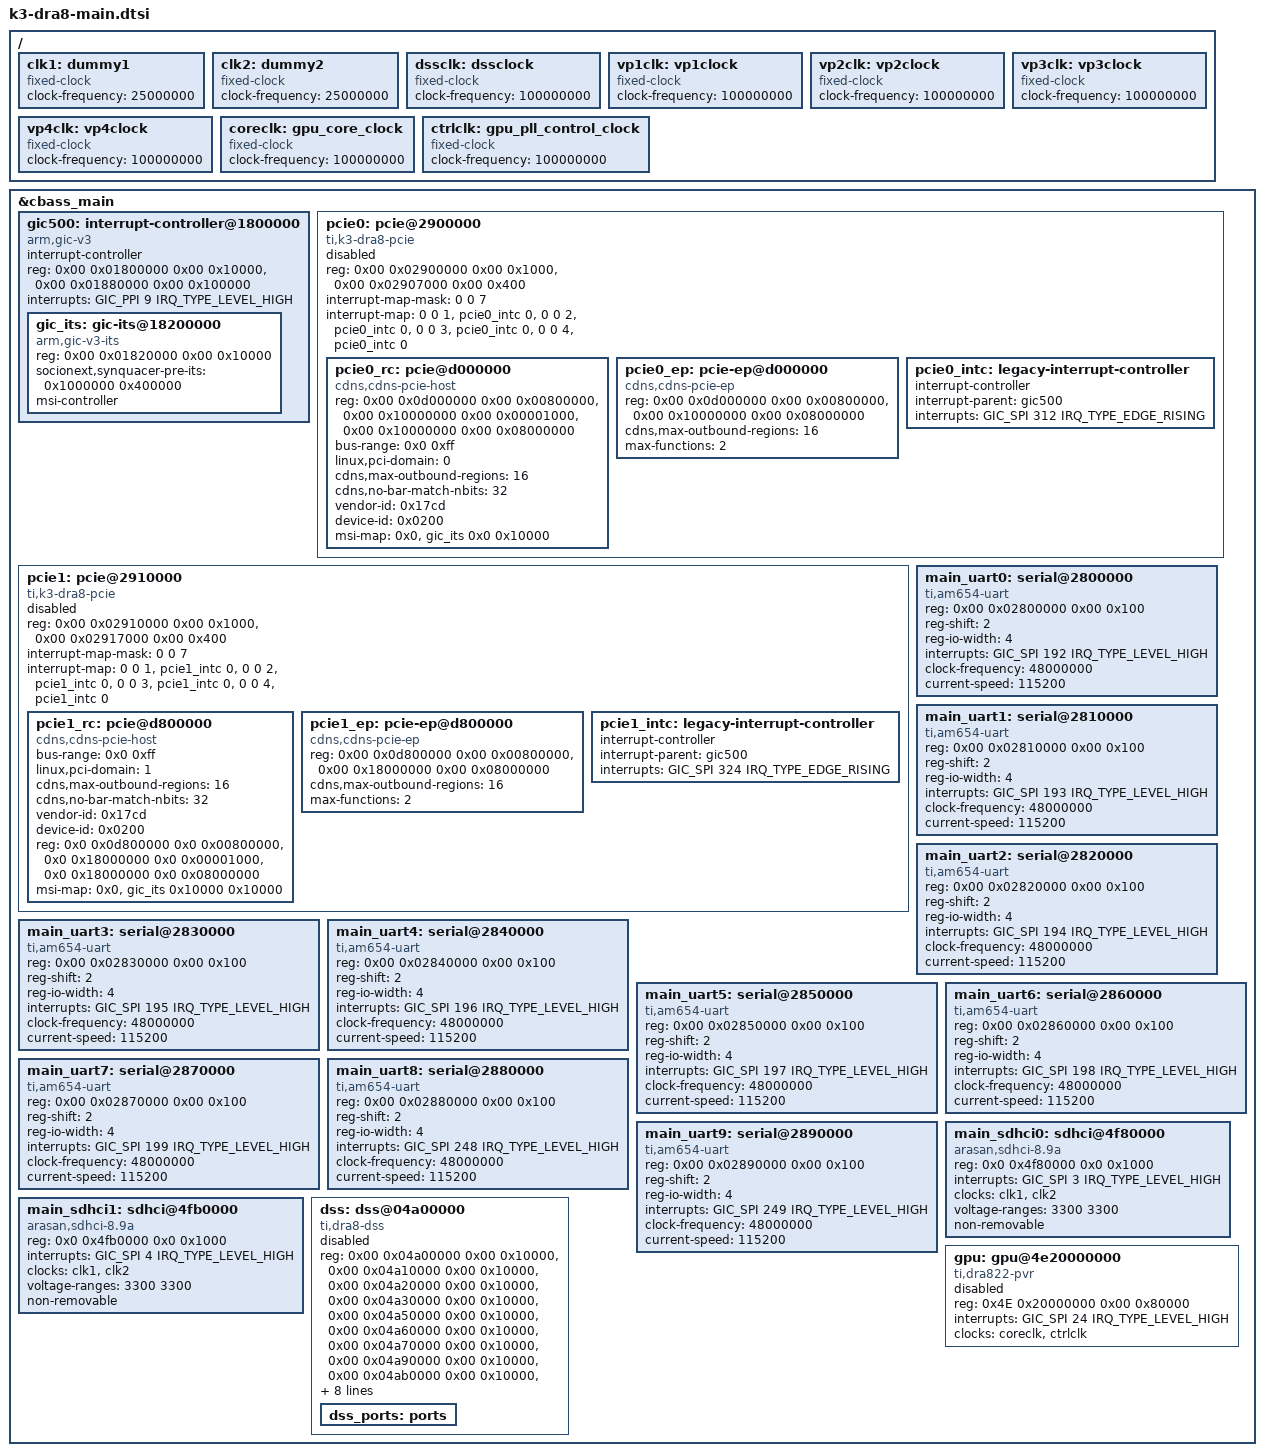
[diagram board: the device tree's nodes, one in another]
// SPDX-License-Identifier: GPL-2.0
/*
 * Device Tree Source for DRA8 SoC Family Main Domain peripherals
 *
 * Copyright (C) 2016-2018 Texas Instruments Incorporated - http://www.ti.com/
 */

/ {
	clk1: dummy1 {
		compatible = "fixed-clock";
		#clock-cells = <0>;
		clock-frequency = <25000000>;
	};

	clk2: dummy2 {
		compatible = "fixed-clock";
		#clock-cells = <0>;
		clock-frequency = <25000000>;
	};

	dssclk: dssclock {
		compatible = "fixed-clock";
		#clock-cells = <0>;
		clock-frequency = <100000000>;
	};

	vp1clk: vp1clock {
		compatible = "fixed-clock";
		#clock-cells = <0>;
		clock-frequency = <100000000>;
	};

	vp2clk: vp2clock {
		compatible = "fixed-clock";
		#clock-cells = <0>;
		clock-frequency = <100000000>;
	};

	vp3clk: vp3clock {
		compatible = "fixed-clock";
		#clock-cells = <0>;
		clock-frequency = <100000000>;
	};

	vp4clk: vp4clock {
		compatible = "fixed-clock";
		#clock-cells = <0>;
		clock-frequency = <100000000>;
	};

	coreclk: gpu_core_clock {
		compatible = "fixed-clock";
		#clock-cells = <0>;
		clock-frequency = <100000000>;
	};

	ctrlclk: gpu_pll_control_clock {
		compatible = "fixed-clock";
		#clock-cells = <0>;
		clock-frequency = <100000000>;
	};
};

&cbass_main {
	gic500: interrupt-controller@1800000 {
		compatible = "arm,gic-v3";
		#address-cells = <2>;
		#size-cells = <2>;
		ranges;
		#interrupt-cells = <3>;
		interrupt-controller;
		reg = <0x00 0x01800000 0x00 0x10000>,	/* GICD */
		      <0x00 0x01880000 0x00 0x100000>;	/* GICR */
		/*
		 * vcpumntirq:
		 * virtual CPU interface maintenance interrupt
		 */
		interrupts = <GIC_PPI 9 IRQ_TYPE_LEVEL_HIGH>;

		gic_its: gic-its@18200000 {
			compatible = "arm,gic-v3-its";
			reg = <0x00 0x01820000 0x00 0x10000>;
			socionext,synquacer-pre-its = <0x1000000 0x400000>;
			msi-controller;
			#msi-cells = <1>;
		};
	};

	pcie0: pcie@2900000 {
		compatible = "ti,k3-dra8-pcie";
		reg = <0x00 0x02900000 0x00 0x1000>,
		      <0x00 0x02907000 0x00 0x400>;
		reg-names = "intd_cfg", "user_cfg";
		#address-cells = <2>;
		#size-cells = <2>;
		ranges;
		#interrupt-cells = <1>;
		interrupt-map-mask = <0 0 7>;
		interrupt-map = <0 0 1 &pcie0_intc 0>, /* INT A */
				<0 0 2 &pcie0_intc 0>, /* INT B */
				<0 0 3 &pcie0_intc 0>, /* INT C */
				<0 0 4 &pcie0_intc 0>; /* INT D */
		status = "disabled";

		pcie0_rc: pcie@d000000 {
			compatible = "cdns,cdns-pcie-host";
			reg = <0x00 0x0d000000 0x00 0x00800000>,
			      <0x00 0x10000000 0x00 0x00001000>,
			      <0x00 0x10000000 0x00 0x08000000>;
			reg-names = "reg", "cfg", "mem";
			device_type = "pci";
			#address-cells = <3>;
			#size-cells = <2>;
			bus-range = <0x0 0xff>;
			linux,pci-domain = <0>;
			cdns,max-outbound-regions = <16>;
			cdns,no-bar-match-nbits = <32>;
			vendor-id = /bits/ 16 <0x17cd>;
			device-id = /bits/ 16 <0x0200>;
			msi-map = <0x0 &gic_its 0x0 0x10000>;
			ranges = <0x01000000 0x0 0x10001000  0x00 0x10001000  0x0 0x0010000>,
				 <0x02000000 0x0 0x10011000  0x00 0x10011000  0x0 0x7fef000>;
		};

		pcie0_ep: pcie-ep@d000000 {
			compatible = "cdns,cdns-pcie-ep";
			reg = <0x00 0x0d000000 0x00 0x00800000>,
			      <0x00 0x10000000 0x00 0x08000000>;
			reg-names = "reg", "mem";
			cdns,max-outbound-regions = <16>;
			max-functions = /bits/ 8 <2>;
		};

		pcie0_intc: legacy-interrupt-controller {
			interrupt-controller;
			#interrupt-cells = <1>;
			interrupt-parent = <&gic500>;
			interrupts = <GIC_SPI 312 IRQ_TYPE_EDGE_RISING>;
		};
	};

	pcie1: pcie@2910000 {
		compatible = "ti,k3-dra8-pcie";
		reg = <0x00 0x02910000 0x00 0x1000>,
		      <0x00 0x02917000 0x00 0x400>;
		reg-names = "intd_cfg", "user_cfg";
		#address-cells = <2>;
		#size-cells = <2>;
		ranges;
		#interrupt-cells = <1>;
		interrupt-map-mask = <0 0 7>;
		interrupt-map = <0 0 1 &pcie1_intc 0>, /* INT A */
				<0 0 2 &pcie1_intc 0>, /* INT B */
				<0 0 3 &pcie1_intc 0>, /* INT C */
				<0 0 4 &pcie1_intc 0>; /* INT D */
		status = "disabled";

		pcie1_rc: pcie@d800000 {
			compatible = "cdns,cdns-pcie-host";
			device_type = "pci";
			#address-cells = <3>;
			#size-cells = <2>;
			bus-range = <0x0 0xff>;
			linux,pci-domain = <1>;
			cdns,max-outbound-regions = <16>;
			cdns,no-bar-match-nbits = <32>;
			vendor-id = /bits/ 16 <0x17cd>;
			device-id = /bits/ 16 <0x0200>;
			reg = <0x0 0x0d800000 0x0 0x00800000>,
			      <0x0 0x18000000 0x0 0x00001000>,
			      <0x0 0x18000000 0x0 0x08000000>;
			reg-names = "reg", "cfg", "mem";
			msi-map = <0x0 &gic_its 0x10000 0x10000>;
			ranges = <0x01000000 0x0 0x18001000  0x00 0x18001000  0x0 0x0010000>,
				 <0x02000000 0x0 0x18011000  0x00 0x18011000  0x0 0x7fef000>;
		};

		pcie1_ep: pcie-ep@d800000 {
			compatible = "cdns,cdns-pcie-ep";
			reg = <0x00 0x0d800000 0x00 0x00800000>,
			      <0x00 0x18000000 0x00 0x08000000>;
			reg-names = "reg", "mem";
			cdns,max-outbound-regions = <16>;
			max-functions = /bits/ 8 <2>;
		};

		pcie1_intc: legacy-interrupt-controller {
			interrupt-controller;
			#interrupt-cells = <1>;
			interrupt-parent = <&gic500>;
			interrupts = <GIC_SPI 324 IRQ_TYPE_EDGE_RISING>;
		};
	};

	main_uart0: serial@2800000 {
		compatible = "ti,am654-uart";
		reg = <0x00 0x02800000 0x00 0x100>;
		reg-shift = <2>;
		reg-io-width = <4>;
		interrupts = <GIC_SPI 192 IRQ_TYPE_LEVEL_HIGH>;
		clock-frequency = <48000000>;
		current-speed = <115200>;
	};

	main_uart1: serial@2810000 {
		compatible = "ti,am654-uart";
		reg = <0x00 0x02810000 0x00 0x100>;
		reg-shift = <2>;
		reg-io-width = <4>;
		interrupts = <GIC_SPI 193 IRQ_TYPE_LEVEL_HIGH>;
		clock-frequency = <48000000>;
		current-speed = <115200>;
	};

	main_uart2: serial@2820000 {
		compatible = "ti,am654-uart";
		reg = <0x00 0x02820000 0x00 0x100>;
		reg-shift = <2>;
		reg-io-width = <4>;
		interrupts = <GIC_SPI 194 IRQ_TYPE_LEVEL_HIGH>;
		clock-frequency = <48000000>;
		current-speed = <115200>;
	};

	main_uart3: serial@2830000 {
		compatible = "ti,am654-uart";
		reg = <0x00 0x02830000 0x00 0x100>;
		reg-shift = <2>;
		reg-io-width = <4>;
		interrupts = <GIC_SPI 195 IRQ_TYPE_LEVEL_HIGH>;
		clock-frequency = <48000000>;
		current-speed = <115200>;
	};

	main_uart4: serial@2840000 {
		compatible = "ti,am654-uart";
		reg = <0x00 0x02840000 0x00 0x100>;
		reg-shift = <2>;
		reg-io-width = <4>;
		interrupts = <GIC_SPI 196 IRQ_TYPE_LEVEL_HIGH>;
		clock-frequency = <48000000>;
		current-speed = <115200>;
	};

	main_uart5: serial@2850000 {
		compatible = "ti,am654-uart";
		reg = <0x00 0x02850000 0x00 0x100>;
		reg-shift = <2>;
		reg-io-width = <4>;
		interrupts = <GIC_SPI 197 IRQ_TYPE_LEVEL_HIGH>;
		clock-frequency = <48000000>;
		current-speed = <115200>;
	};

	main_uart6: serial@2860000 {
		compatible = "ti,am654-uart";
		reg = <0x00 0x02860000 0x00 0x100>;
		reg-shift = <2>;
		reg-io-width = <4>;
		interrupts = <GIC_SPI 198 IRQ_TYPE_LEVEL_HIGH>;
		clock-frequency = <48000000>;
		current-speed = <115200>;
	};

	main_uart7: serial@2870000 {
		compatible = "ti,am654-uart";
		reg = <0x00 0x02870000 0x00 0x100>;
		reg-shift = <2>;
		reg-io-width = <4>;
		interrupts = <GIC_SPI 199 IRQ_TYPE_LEVEL_HIGH>;
		clock-frequency = <48000000>;
		current-speed = <115200>;
	};

	main_uart8: serial@2880000 {
		compatible = "ti,am654-uart";
		reg = <0x00 0x02880000 0x00 0x100>;
		reg-shift = <2>;
		reg-io-width = <4>;
		interrupts = <GIC_SPI 248 IRQ_TYPE_LEVEL_HIGH>;
		clock-frequency = <48000000>;
		current-speed = <115200>;
	};

	main_uart9: serial@2890000 {
		compatible = "ti,am654-uart";
		reg = <0x00 0x02890000 0x00 0x100>;
		reg-shift = <2>;
		reg-io-width = <4>;
		interrupts = <GIC_SPI 249 IRQ_TYPE_LEVEL_HIGH>;
		clock-frequency = <48000000>;
		current-speed = <115200>;
	};

	main_sdhci0: sdhci@4f80000 {
		compatible = "arasan,sdhci-8.9a";
		reg = <0x0 0x4f80000 0x0 0x1000>;
		interrupts = <GIC_SPI 3 IRQ_TYPE_LEVEL_HIGH>;
		clock-names = "clk_xin", "clk_ahb";
		clocks = <&clk1>, <&clk2>;
		voltage-ranges = <3300 3300>;
		non-removable;
	};

	main_sdhci1: sdhci@4fb0000 {
		compatible = "arasan,sdhci-8.9a";
		reg = <0x0 0x4fb0000 0x0 0x1000>;
		interrupts = <GIC_SPI 4 IRQ_TYPE_LEVEL_HIGH>;
		clock-names = "clk_xin", "clk_ahb";
		clocks = <&clk1>, <&clk2>;
		voltage-ranges = <3300 3300>;
		non-removable;
	};

	dss: dss@04a00000 {
		compatible = "ti,dra8-dss";
		reg =
			<0x00 0x04a00000 0x00 0x10000>, /* common */
			<0x00 0x04a10000 0x00 0x10000>, /* common1*/

			<0x00 0x04a20000 0x00 0x10000>, /* vidl1 */
			<0x00 0x04a30000 0x00 0x10000>, /* vidl2 */
			<0x00 0x04a50000 0x00 0x10000>, /* vid1 */
			<0x00 0x04a60000 0x00 0x10000>, /* vid2 */

			<0x00 0x04a70000 0x00 0x10000>, /* ovr1 */
			<0x00 0x04a90000 0x00 0x10000>, /* ovr2 */
			<0x00 0x04ab0000 0x00 0x10000>, /* ovr3 */
			<0x00 0x04ad0000 0x00 0x10000>, /* ovr4 */

			<0x00 0x04a80000 0x00 0x10000>, /* vp1 */
			<0x00 0x04aa0000 0x00 0x10000>, /* vp2 */
			<0x00 0x04ac0000 0x00 0x10000>, /* vp3 */
			<0x00 0x04ae0000 0x00 0x10000>, /* vp4 */
			<0x00 0x04af0000 0x00 0x10000>; /* wb */

		reg-names = "common", "common1",
			"vidl1", "vidl2","vid1","vid2",
			"ovr1", "ovr2", "ovr3", "ovr4",
			"vp1", "vp2", "vp3", "vp4",
			"wb";

		clocks = <&dssclk>, <&vp1clk>, <&vp2clk>, <&vp3clk>,
				<&vp4clk>;
		clock-names = "fck", "vp1", "vp2", "vp3", "vp4";

		interrupts = <GIC_SPI 602 IRQ_TYPE_EDGE_RISING>;

		status = "disabled";

		dss_ports: ports {
			#address-cells = <1>;
			#size-cells = <0>;
		};
	};

	gpu: gpu@4e20000000 {
		compatible = "ti,dra822-pvr", "img,pvr-ge8430";
		reg = <0x4E 0x20000000 0x00 0x80000>;
		reg-names = "gpu_regs";
		interrupts = <GIC_SPI 24 IRQ_TYPE_LEVEL_HIGH>;
		clocks = <&coreclk>, <&ctrlclk>;
		clock-names = "core", "ctrl";
		status = "disabled";
	};
};
